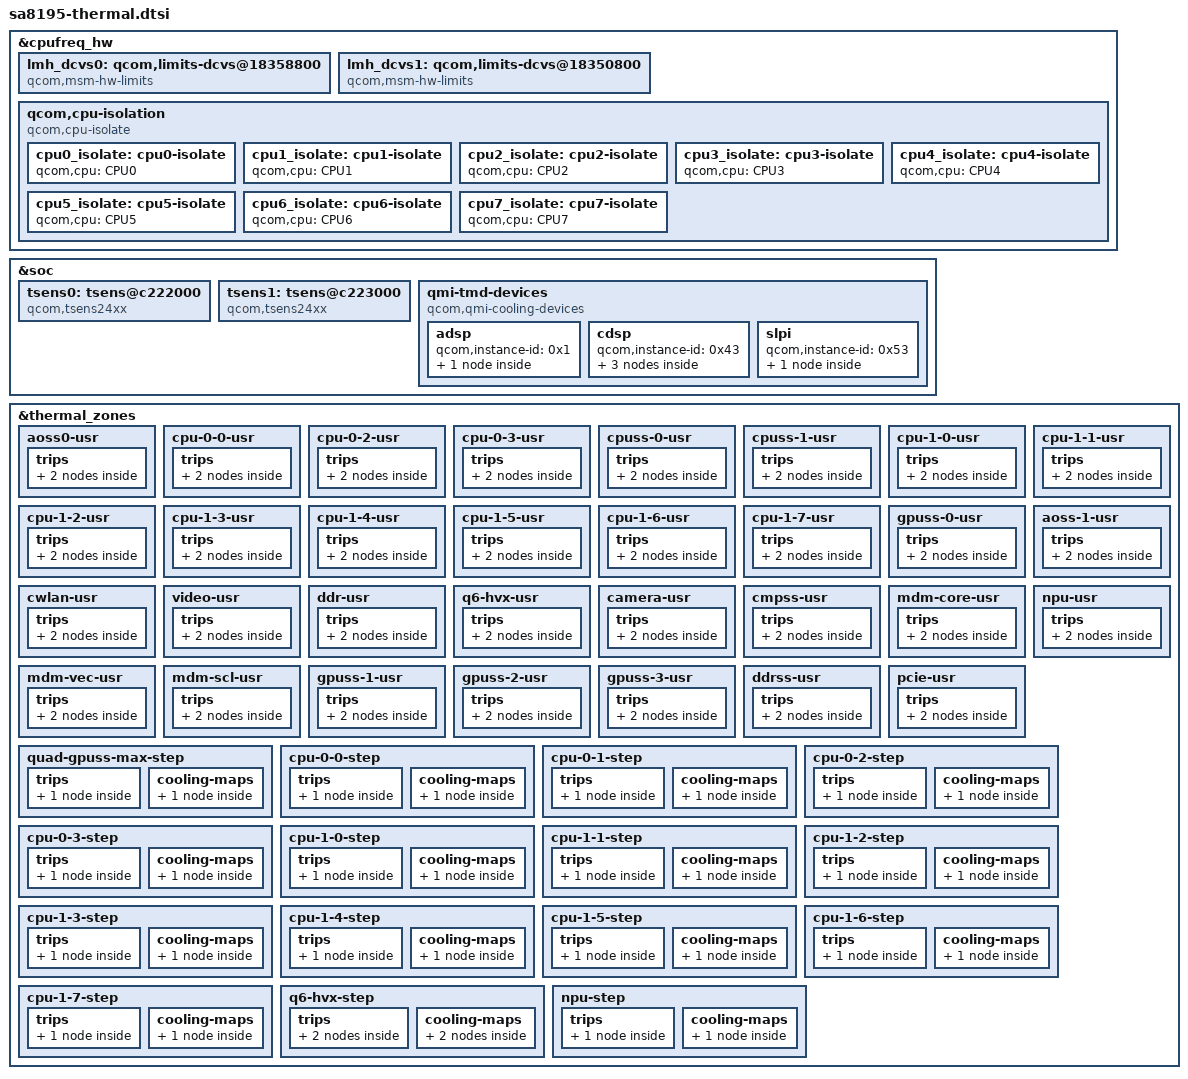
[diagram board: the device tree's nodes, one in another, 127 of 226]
#include <dt-bindings/thermal/thermal_qti.h>

&cpufreq_hw {
	#address-cells = <1>;
	#size-cells = <1>;
	lmh_dcvs0: qcom,limits-dcvs@18358800 {
		compatible = "qcom,msm-hw-limits";
		interrupts = <GIC_SPI 32 IRQ_TYPE_LEVEL_HIGH>;
		qcom,affinity = <0>;
		reg = <0x18358800 0x1000>,
			<0x18323000 0x1000>;
	};

	lmh_dcvs1: qcom,limits-dcvs@18350800 {
		compatible = "qcom,msm-hw-limits";
		interrupts = <GIC_SPI 33 IRQ_TYPE_LEVEL_HIGH>;
		qcom,affinity = <1>;
		reg = <0x18350800 0x1000>,
			<0x18325800 0x1000>;
		isens_vref_0p8-supply = <&pm8150_2_l5_ao>;
		isens-vref-0p8-settings = <880000 880000 20000>;
		isens_vref_1p8-supply = <&pm8150_1_l12_ao>;
		isens-vref-1p8-settings = <1800000 1800000 20000>;
	};

	qcom,cpu-isolation {
		compatible = "qcom,cpu-isolate";
		cpu0_isolate: cpu0-isolate {
			qcom,cpu = <&CPU0>;
			#cooling-cells = <2>;
		};

		cpu1_isolate: cpu1-isolate {
			qcom,cpu = <&CPU1>;
			#cooling-cells = <2>;
		};

		cpu2_isolate: cpu2-isolate {
			qcom,cpu = <&CPU2>;
			#cooling-cells = <2>;
		};

		cpu3_isolate: cpu3-isolate {
			qcom,cpu = <&CPU3>;
			#cooling-cells = <2>;
		};

		cpu4_isolate: cpu4-isolate {
			qcom,cpu = <&CPU4>;
			#cooling-cells = <2>;
		};

		cpu5_isolate: cpu5-isolate {
			qcom,cpu = <&CPU5>;
			#cooling-cells = <2>;
		};

		cpu6_isolate: cpu6-isolate {
			qcom,cpu = <&CPU6>;
			#cooling-cells = <2>;
		};

		cpu7_isolate: cpu7-isolate {
			qcom,cpu = <&CPU7>;
			#cooling-cells = <2>;
		};
	};
};

&soc {
	tsens0: tsens@c222000 {
		compatible = "qcom,tsens24xx";
		reg = <0xc222000 0x4>,
			<0xc263000 0x1ff>;
		reg-names = "tsens_srot_physical",
				"tsens_tm_physical";
		interrupts = <GIC_SPI 506 IRQ_TYPE_LEVEL_HIGH>,
				<GIC_SPI 508 IRQ_TYPE_LEVEL_HIGH>;
		interrupt-names = "tsens-upper-lower", "tsens-critical";
		tsens-reinit-wa;
		#thermal-sensor-cells = <1>;
	};

	tsens1: tsens@c223000 {
		compatible = "qcom,tsens24xx";
		reg = <0xc223000 0x4>,
			<0xc265000 0x1ff>;
		reg-names = "tsens_srot_physical",
			"tsens_tm_physical";
		interrupts = <GIC_SPI 507 IRQ_TYPE_LEVEL_HIGH>,
				<GIC_SPI 509 IRQ_TYPE_LEVEL_HIGH>;
		interrupt-names = "tsens-upper-lower", "tsens-critical";
		tsens-reinit-wa;
		#thermal-sensor-cells = <1>;
	};

	qmi-tmd-devices {
		compatible = "qcom,qmi-cooling-devices";

		adsp {
			qcom,instance-id = <0x1>;

			adsp_vdd: adsp_vdd {
				qcom,qmi-dev-name = "cpuv_restriction_cold";
				#cooling-cells = <2>;
			};
		};

		cdsp {
			qcom,instance-id = <0x43>;

			cdsp_vdd: cdsp_vdd {
				qcom,qmi-dev-name = "cpuv_restriction_cold";
				#cooling-cells = <2>;
			};

			cdsp_sw: cdsp {
				qcom,qmi-dev-name = "cdsp_sw";
				#cooling-cells = <2>;
			};

			cdsp_hw: hvx {
				qcom,qmi-dev-name = "cdsp_hw";
				#cooling-cells = <2>;
			};
		};

		slpi {
			qcom,instance-id = <0x53>;

			slpi_vdd: slpi_vdd {
				qcom,qmi-dev-name = "cpuv_restriction_cold";
				#cooling-cells = <2>;
			};
		};
	};
};

&thermal_zones {
	aoss0-usr {
		polling-delay-passive = <0>;
		polling-delay = <0>;
		thermal-governor = "user_space";
		thermal-sensors = <&tsens0 0>;
		trips {
			active-config0 {
				temperature = <125000>;
				hysteresis = <1000>;
				type = "passive";
			};

			reset-mon-cfg {
				temperature = <115000>;
				hysteresis = <5000>;
				type = "passive";
			};
		};
	};

	cpu-0-0-usr {
		polling-delay-passive = <0>;
		polling-delay = <0>;
		thermal-governor = "user_space";
		thermal-sensors = <&tsens0 1>;
		trips {
			active-config0 {
				temperature = <125000>;
				hysteresis = <1000>;
				type = "passive";
			};

			reset-mon-cfg {
				temperature = <115000>;
				hysteresis = <5000>;
				type = "passive";
			};
		};
	};

	cpu-0-2-usr {
		polling-delay-passive = <0>;
		polling-delay = <0>;
		thermal-governor = "user_space";
		thermal-sensors = <&tsens0 3>;
		trips {
			active-config0 {
				temperature = <125000>;
				hysteresis = <1000>;
				type = "passive";
			};

			reset-mon-cfg {
				temperature = <115000>;
				hysteresis = <5000>;
				type = "passive";
			};
		};
	};

	cpu-0-3-usr {
		polling-delay-passive = <0>;
		polling-delay = <0>;
		thermal-sensors = <&tsens0 4>;
		thermal-governor = "user_space";
		trips {
			active-config0 {
				temperature = <125000>;
				hysteresis = <1000>;
				type = "passive";
			};

			reset-mon-cfg {
				temperature = <115000>;
				hysteresis = <5000>;
				type = "passive";
			};
		};
	};

	cpuss-0-usr {
		polling-delay-passive = <0>;
		polling-delay = <0>;
		thermal-sensors = <&tsens0 5>;
		thermal-governor = "user_space";
		trips {
			active-config0 {
				temperature = <125000>;
				hysteresis = <1000>;
				type = "passive";
			};

			reset-mon-cfg {
				temperature = <115000>;
				hysteresis = <5000>;
				type = "passive";
			};
		};
	};

	cpuss-1-usr {
		polling-delay-passive = <0>;
		polling-delay = <0>;
		thermal-sensors = <&tsens0 6>;
		thermal-governor = "user_space";
		trips {
			active-config0 {
				temperature = <125000>;
				hysteresis = <1000>;
				type = "passive";
			};

			reset-mon-cfg {
				temperature = <115000>;
				hysteresis = <5000>;
				type = "passive";
			};
		};
	};

	cpu-1-0-usr {
		polling-delay-passive = <0>;
		polling-delay = <0>;
		thermal-sensors = <&tsens0 7>;
		thermal-governor = "user_space";
		trips {
			active-config0 {
				temperature = <125000>;
				hysteresis = <1000>;
				type = "passive";
			};

			reset-mon-cfg {
				temperature = <115000>;
				hysteresis = <5000>;
				type = "passive";
			};
		};
	};

	cpu-1-1-usr {
		polling-delay-passive = <0>;
		polling-delay = <0>;
		thermal-sensors = <&tsens0 8>;
		thermal-governor = "user_space";
		trips {
			active-config0 {
				temperature = <125000>;
				hysteresis = <1000>;
				type = "passive";
			};

			reset-mon-cfg {
				temperature = <115000>;
				hysteresis = <5000>;
				type = "passive";
			};
		};
	};

	cpu-1-2-usr {
		polling-delay-passive = <0>;
		polling-delay = <0>;
		thermal-sensors = <&tsens0 9>;
		thermal-governor = "user_space";
		trips {
			active-config0 {
				temperature = <125000>;
				hysteresis = <1000>;
				type = "passive";
			};

			reset-mon-cfg {
				temperature = <115000>;
				hysteresis = <5000>;
				type = "passive";
			};
		};
	};

	cpu-1-3-usr {
		polling-delay-passive = <0>;
		polling-delay = <0>;
		thermal-sensors = <&tsens0 10>;
		thermal-governor = "user_space";
		trips {
			active-config0 {
				temperature = <125000>;
				hysteresis = <1000>;
				type = "passive";
			};

			reset-mon-cfg {
				temperature = <115000>;
				hysteresis = <5000>;
				type = "passive";
			};
		};
	};

	cpu-1-4-usr {
		polling-delay-passive = <0>;
		polling-delay = <0>;
		thermal-sensors = <&tsens0 11>;
		thermal-governor = "user_space";
		trips {
			active-config0 {
				temperature = <125000>;
				hysteresis = <1000>;
				type = "passive";
			};

			reset-mon-cfg {
				temperature = <115000>;
				hysteresis = <5000>;
				type = "passive";
			};
		};
	};

	cpu-1-5-usr {
		polling-delay-passive = <0>;
		polling-delay = <0>;
		thermal-sensors = <&tsens0 12>;
		thermal-governor = "user_space";
		trips {
			active-config0 {
				temperature = <125000>;
				hysteresis = <1000>;
				type = "passive";
			};

			reset-mon-cfg {
				temperature = <115000>;
				hysteresis = <5000>;
				type = "passive";
			};
		};
	};

	cpu-1-6-usr {
		polling-delay-passive = <0>;
		polling-delay = <0>;
		thermal-sensors = <&tsens0 13>;
		thermal-governor = "user_space";
		trips {
			active-config0 {
				temperature = <125000>;
				hysteresis = <1000>;
				type = "passive";
			};

			reset-mon-cfg {
				temperature = <115000>;
				hysteresis = <5000>;
				type = "passive";
			};
		};
	};

	cpu-1-7-usr {
		polling-delay-passive = <0>;
		polling-delay = <0>;
		thermal-sensors = <&tsens0 14>;
		thermal-governor = "user_space";
		trips {
			active-config0 {
				temperature = <125000>;
				hysteresis = <1000>;
				type = "passive";
			};

			reset-mon-cfg {
				temperature = <115000>;
				hysteresis = <5000>;
				type = "passive";
			};
		};
	};

	gpuss-0-usr {
		polling-delay-passive = <0>;
		polling-delay = <0>;
		thermal-sensors = <&tsens0 15>;
		thermal-governor = "user_space";
		trips {
			active-config0 {
				temperature = <125000>;
				hysteresis = <1000>;
				type = "passive";
			};

			reset-mon-cfg {
				temperature = <115000>;
				hysteresis = <5000>;
				type = "passive";
			};
		};
	};

	aoss-1-usr {
		polling-delay-passive = <0>;
		polling-delay = <0>;
		thermal-sensors = <&tsens1 0>;
		thermal-governor = "user_space";
		trips {
			active-config0 {
				temperature = <125000>;
				hysteresis = <1000>;
				type = "passive";
			};

			reset-mon-cfg {
				temperature = <115000>;
				hysteresis = <5000>;
				type = "passive";
			};
		};
	};

	cwlan-usr {
		polling-delay-passive = <0>;
		polling-delay = <0>;
		thermal-sensors = <&tsens1 1>;
		thermal-governor = "user_space";
		trips {
			active-config0 {
				temperature = <125000>;
				hysteresis = <1000>;
				type = "passive";
			};

			reset-mon-cfg {
				temperature = <115000>;
				hysteresis = <5000>;
				type = "passive";
			};
		};
	};

	video-usr {
		polling-delay-passive = <0>;
		polling-delay = <0>;
		thermal-sensors = <&tsens1 2>;
		thermal-governor = "user_space";
		trips {
			active-config0 {
				temperature = <125000>;
				hysteresis = <1000>;
				type = "passive";
			};

			reset-mon-cfg {
				temperature = <115000>;
				hysteresis = <5000>;
				type = "passive";
			};
		};
	};

	ddr-usr {
		polling-delay-passive = <0>;
		polling-delay = <0>;
		thermal-sensors = <&tsens1 3>;
		thermal-governor = "user_space";
		trips {
			active-config0 {
				temperature = <125000>;
				hysteresis = <1000>;
				type = "passive";
			};

			reset-mon-cfg {
				temperature = <115000>;
				hysteresis = <5000>;
				type = "passive";
			};
		};
	};

	q6-hvx-usr {
		polling-delay-passive = <0>;
		polling-delay = <0>;
		thermal-sensors = <&tsens1 4>;
		thermal-governor = "user_space";
		trips {
			active-config0 {
				temperature = <125000>;
				hysteresis = <1000>;
				type = "passive";
			};

			reset-mon-cfg {
				temperature = <115000>;
				hysteresis = <5000>;
				type = "passive";
			};
		};
	};

	camera-usr {
		polling-delay-passive = <0>;
		polling-delay = <0>;
		thermal-sensors = <&tsens1 5>;
		thermal-governor = "user_space";
		trips {
			active-config0 {
				temperature = <125000>;
				hysteresis = <1000>;
				type = "passive";
			};

			reset-mon-cfg {
				temperature = <115000>;
				hysteresis = <5000>;
				type = "passive";
			};
		};
	};

	cmpss-usr {
		polling-delay-passive = <0>;
		polling-delay = <0>;
		thermal-sensors = <&tsens1 6>;
		thermal-governor = "user_space";
		trips {
			active-config0 {
				temperature = <125000>;
				hysteresis = <1000>;
				type = "passive";
			};

			reset-mon-cfg {
				temperature = <115000>;
				hysteresis = <5000>;
				type = "passive";
			};
		};
	};

	mdm-core-usr {
		polling-delay-passive = <0>;
		polling-delay = <0>;
		thermal-sensors = <&tsens1 7>;
		thermal-governor = "user_space";
		trips {
			active-config0 {
				temperature = <125000>;
				hysteresis = <1000>;
				type = "passive";
			};

			reset-mon-cfg {
				temperature = <115000>;
				hysteresis = <5000>;
				type = "passive";
			};
		};
	};

	npu-usr {
		polling-delay-passive = <0>;
		polling-delay = <0>;
		thermal-sensors = <&tsens1 8>;
		thermal-governor = "user_space";
		trips {
			active-config0 {
				temperature = <125000>;
				hysteresis = <1000>;
				type = "passive";
			};

			reset-mon-cfg {
				temperature = <115000>;
				hysteresis = <5000>;
				type = "passive";
			};
		};
	};

	mdm-vec-usr {
		polling-delay-passive = <0>;
		polling-delay = <0>;
		thermal-sensors = <&tsens1 9>;
		thermal-governor = "user_space";
		trips {
			active-config0 {
				temperature = <125000>;
				hysteresis = <1000>;
				type = "passive";
			};

			reset-mon-cfg {
				temperature = <115000>;
				hysteresis = <5000>;
				type = "passive";
			};
		};
	};

	mdm-scl-usr {
		polling-delay-passive = <0>;
		polling-delay = <0>;
		thermal-sensors = <&tsens1 10>;
		thermal-governor = "user_space";
		trips {
			active-config0 {
				temperature = <125000>;
				hysteresis = <1000>;
				type = "passive";
			};

			reset-mon-cfg {
				temperature = <115000>;
				hysteresis = <5000>;
				type = "passive";
			};
		};
	};

	gpuss-1-usr {
		polling-delay-passive = <0>;
		polling-delay = <0>;
		thermal-governor = "user_space";
		thermal-sensors = <&tsens1 11>;
		trips {
			active-config0 {
				temperature = <125000>;
				hysteresis = <1000>;
				type = "passive";
			};

			reset-mon-cfg {
				temperature = <115000>;
				hysteresis = <5000>;
				type = "passive";
			};
		};
	};

	gpuss-2-usr {
		polling-delay-passive = <0>;
		polling-delay = <0>;
		thermal-governor = "user_space";
		thermal-sensors = <&tsens1 12>;
		trips {
			active-config0 {
				temperature = <125000>;
				hysteresis = <1000>;
				type = "passive";
			};

			reset-mon-cfg {
				temperature = <115000>;
				hysteresis = <5000>;
				type = "passive";
			};
		};
	};

	gpuss-3-usr {
		polling-delay-passive = <0>;
		polling-delay = <0>;
		thermal-governor = "user_space";
		thermal-sensors = <&tsens1 13>;
		trips {
			active-config0 {
				temperature = <125000>;
				hysteresis = <1000>;
				type = "passive";
			};

			reset-mon-cfg {
				temperature = <115000>;
				hysteresis = <5000>;
				type = "passive";
			};
		};
	};

	ddrss-usr {
		polling-delay-passive = <0>;
		polling-delay = <0>;
		thermal-governor = "user_space";
		thermal-sensors = <&tsens1 14>;
		trips {
			active-config0 {
				temperature = <125000>;
				hysteresis = <1000>;
				type = "passive";
			};

			reset-mon-cfg {
				temperature = <115000>;
				hysteresis = <5000>;
				type = "passive";
			};
		};
	};

	pcie-usr {
		polling-delay-passive = <0>;
		polling-delay = <0>;
		thermal-governor = "user_space";
		thermal-sensors = <&tsens1 15>;
		trips {
			active-config0 {
				temperature = <125000>;
				hysteresis = <1000>;
				type = "passive";
			};

			reset-mon-cfg {
				temperature = <115000>;
				hysteresis = <5000>;
				type = "passive";
			};
		};
	};

	quad-gpuss-max-step {
		polling-delay-passive = <10>;
		polling-delay = <100>;
		thermal-governor = "step_wise";
		thermal-sensors = <&tsens0 15>, <&tsens1 11>,
					<&tsens1 12>, <&tsens1 13>;
		sensor-aggregation = <AGGREGATE_MAX_VALUE>;
		trips {
			gpu_trip0: gpu-trip0 {
				temperature = <105000>;
				hysteresis = <0>;
				type = "passive";
			};
		};

		cooling-maps {
			gpu_cdev {
				trip = <&gpu_trip0>;
				cooling-device = <&msm_gpu THERMAL_NO_LIMIT
							THERMAL_NO_LIMIT>;
			};
		};
	};

	cpu-0-0-step {
		polling-delay-passive = <0>;
		polling-delay = <0>;
		thermal-governor = "step_wise";
		thermal-sensors = <&tsens0 1>;
		trips {
			cpu00_config: cpu00-config {
				temperature = <115000>;
				hysteresis = <10000>;
				type = "passive";
			};
		};

		cooling-maps {
			cpu00_cdev {
				trip = <&cpu00_config>;
				cooling-device = <&cpu0_isolate 1 1>;
			};
		};
	};

	cpu-0-1-step {
		polling-delay-passive = <0>;
		polling-delay = <0>;
		thermal-governor = "step_wise";
		thermal-sensors = <&tsens0 2>;
		trips {
			cpu01_config: cpu01-config {
				temperature = <115000>;
				hysteresis = <10000>;
				type = "passive";
			};
		};

		cooling-maps {
			cpu01_cdev {
				trip = <&cpu01_config>;
				cooling-device = <&cpu1_isolate 1 1>;
			};
		};
	};

	cpu-0-2-step {
		polling-delay-passive = <0>;
		polling-delay = <0>;
		thermal-governor = "step_wise";
		thermal-sensors = <&tsens0 3>;
		trips {
			cpu02_config: cpu02-config {
				temperature = <115000>;
				hysteresis = <10000>;
				type = "passive";
			};
		};

		cooling-maps {
			cpu02_cdev {
				trip = <&cpu02_config>;
				cooling-device = <&cpu2_isolate 1 1>;
			};
		};
	};

	cpu-0-3-step {
		polling-delay-passive = <0>;
		polling-delay = <0>;
		thermal-sensors = <&tsens0 4>;
		thermal-governor = "step_wise";
		trips {
			cpu03_config: cpu03-config {
				temperature = <115000>;
				hysteresis = <10000>;
				type = "passive";
			};
		};

		cooling-maps {
			cpu03_cdev {
				trip = <&cpu03_config>;
				cooling-device = <&cpu3_isolate 1 1>;
			};
		};
	};

	cpu-1-0-step {
		polling-delay-passive = <0>;
		polling-delay = <0>;
		thermal-sensors = <&tsens0 7>;
		thermal-governor = "step_wise";
		trips {
			cpu10_config: cpu10-config {
				temperature = <115000>;
				hysteresis = <10000>;
				type = "passive";
			};
		};

		cooling-maps {
			cpu10_cdev {
				trip = <&cpu10_config>;
				cooling-device = <&cpu4_isolate 1 1>;
			};
		};
	};

	cpu-1-1-step {
		polling-delay-passive = <0>;
		polling-delay = <0>;
		thermal-sensors = <&tsens0 8>;
		thermal-governor = "step_wise";
		trips {
			cpu11_config: cpu11-config {
				temperature = <115000>;
				hysteresis = <10000>;
				type = "passive";
			};
		};

		cooling-maps {
			cpu11_cdev {
				trip = <&cpu11_config>;
				cooling-device = <&cpu5_isolate 1 1>;
			};
		};
	};

	cpu-1-2-step {
		polling-delay-passive = <0>;
		polling-delay = <0>;
		thermal-sensors = <&tsens0 9>;
		thermal-governor = "step_wise";
		trips {
			cpu12_config: cpu12-config {
				temperature = <115000>;
				hysteresis = <10000>;
				type = "passive";
			};
		};

		cooling-maps {
			cpu12_cdev {
				trip = <&cpu12_config>;
				cooling-device = <&cpu6_isolate 1 1>;
			};
		};
	};

	cpu-1-3-step {
		polling-delay-passive = <0>;
		polling-delay = <0>;
		thermal-sensors = <&tsens0 10>;
		thermal-governor = "step_wise";
		trips {
			cpu13_config: cpu13-config {
				temperature = <115000>;
				hysteresis = <10000>;
				type = "passive";
			};
		};

		cooling-maps {
			cpu13_cdev {
				trip = <&cpu13_config>;
				cooling-device = <&cpu7_isolate 1 1>;
			};
		};
	};

	cpu-1-4-step {
		polling-delay-passive = <0>;
		polling-delay = <0>;
		thermal-sensors = <&tsens0 11>;
		thermal-governor = "step_wise";
		trips {
			cpu14_config: cpu14-config {
				temperature = <115000>;
				hysteresis = <10000>;
				type = "passive";
			};
		};

		cooling-maps {
			cpu14_cdev {
				trip = <&cpu14_config>;
				cooling-device = <&cpu4_isolate 1 1>;
			};
		};
	};

	cpu-1-5-step {
		polling-delay-passive = <0>;
		polling-delay = <0>;
		thermal-sensors = <&tsens0 12>;
		thermal-governor = "step_wise";
		trips {
			cpu15_config: cpu15-config {
				temperature = <115000>;
				hysteresis = <10000>;
				type = "passive";
			};
		};

		cooling-maps {
			cpu15_cdev {
				trip = <&cpu15_config>;
				cooling-device = <&cpu5_isolate 1 1>;
			};
		};
	};

	cpu-1-6-step {
		polling-delay-passive = <0>;
		polling-delay = <0>;
		thermal-sensors = <&tsens0 13>;
		thermal-governor = "step_wise";
		trips {
			cpu16_config: cpu16-config {
				temperature = <115000>;
				hysteresis = <10000>;
				type = "passive";
			};
		};

		cooling-maps {
			cpu16_cdev {
				trip = <&cpu16_config>;
				cooling-device = <&cpu6_isolate 1 1>;
			};
		};
	};

	cpu-1-7-step {
		polling-delay-passive = <0>;
		polling-delay = <0>;
		thermal-sensors = <&tsens0 14>;
		thermal-governor = "step_wise";
		trips {
			cpu17_config: cpu17-config {
				temperature = <115000>;
				hysteresis = <10000>;
				type = "passive";
			};
		};

		cooling-maps {
			cpu17_cdev {
				trip = <&cpu17_config>;
				cooling-device = <&cpu7_isolate 1 1>;
			};
		};
	};

	q6-hvx-step {
		polling-delay-passive = <10>;
		polling-delay = <0>;
		thermal-sensors = <&tsens1 4>;
		thermal-governor = "step_wise";
		trips {
			q6_hvx_trip0: q6-hvx-trip0 {
				temperature = <105000>;
				hysteresis = <0>;
				type = "passive";
			};

			q6_hvx_trip1: q6-hvx-trip1 {
				temperature = <115000>;
				hysteresis = <5000>;
				type = "passive";
			};
		};

		cooling-maps {
			cdsp-cdev0 {
				trip = <&q6_hvx_trip0>;
				cooling-device = <&cdsp_sw THERMAL_NO_LIMIT
							THERMAL_NO_LIMIT>;
			};

			cdsp-cx-cdev0 {
				trip = <&q6_hvx_trip1>;
				cooling-device = <&cdsp_sw THERMAL_MAX_LIMIT
							THERMAL_MAX_LIMIT>;
			};
		};
	};

	npu-step {
		polling-delay-passive = <10>;
		polling-delay = <0>;
		thermal-sensors = <&tsens1 8>;
		thermal-governor = "step_wise";
		trips {
			npu_trip0: npu-trip0 {
				temperature = <105000>;
				hysteresis = <0>;
				type = "passive";
			};
		};

		cooling-maps {
			npu_cdev {
				trip = <&npu_trip0>;
				cooling-device =
					<&msm_npu THERMAL_NO_LIMIT
						THERMAL_NO_LIMIT>;
			};
		};
	};
};
